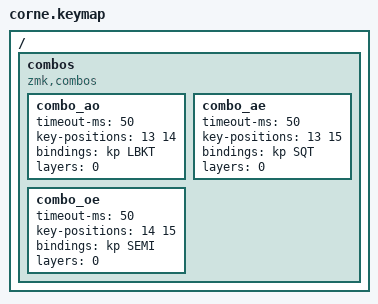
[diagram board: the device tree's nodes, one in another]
// Copyright 2021 Manna Harbour
// https://github.com/manna-harbour/miryoku

#include "../miryoku/custom_config.h"
#include "../miryoku/mapping/42/corne.h"
#include "../miryoku/miryoku.dtsi"

/ {
    combos {
        compatible = "zmk,combos";
        combo_ao {
            timeout-ms = <50>;
            key-positions = <13 14>;
            bindings = <&kp LBKT>;
            layers = <0>;
        };
        
        combo_ae {
            timeout-ms = <50>;
            key-positions = <13 15>;
            bindings = <&kp SQT>;
            layers = <0>;
        };
         
        combo_oe {
            timeout-ms = <50>;
            key-positions = <14 15>;
            bindings = <&kp SEMI>;
            layers = <0>;
        };
    };
};
